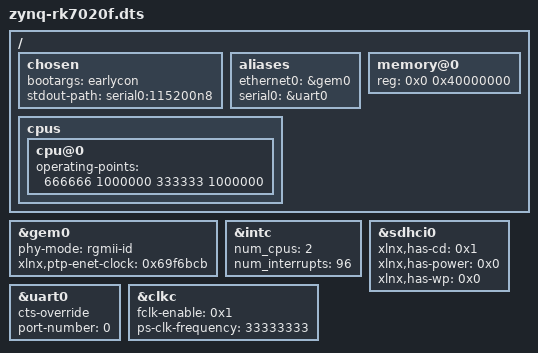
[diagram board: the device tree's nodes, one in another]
/*
 * CAUTION: This file is automatically generated by Xilinx.
 * Version: XSCT 
 * Today is: Tue Sep 24 13:38:00 2024
 */


/dts-v1/;
#include "zynq-7000.dtsi"

/ {
	chosen {
		bootargs = "earlycon";
		stdout-path = "serial0:115200n8";
	};
	aliases {
		ethernet0 = &gem0;
		serial0 = &uart0;
	};
	memory@0 {
		device_type = "memory";
		reg = <0x0 0x40000000>;
	};
};

/ {
	cpus {
		cpu@0 {
			operating-points = <666666 1000000 333333 1000000>;
		};
	};
};
&gem0 {
	bootph-all;
	phy-mode = "rgmii-id";
	status = "okay";
	xlnx,ptp-enet-clock = <0x69f6bcb>;
};
&intc {
	bootph-all;
	num_cpus = <2>;
	num_interrupts = <96>;
};
&sdhci0 {
	bootph-all;
	status = "okay";
	xlnx,has-cd = <0x1>;
	xlnx,has-power = <0x0>;
	xlnx,has-wp = <0x0>;
};
&uart0 {
	bootph-all;
	cts-override ;
	device_type = "serial";
	port-number = <0>;
	status = "okay";
};
&clkc {
	bootph-all;
	fclk-enable = <0x1>;
	ps-clk-frequency = <33333333>;
};
